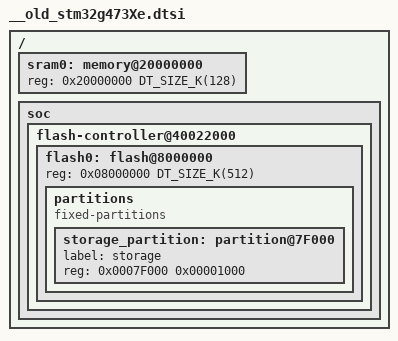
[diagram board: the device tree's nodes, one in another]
/*
 * Copyright (c) 2019 STMicroelectronics.
 *
 * SPDX-License-Identifier: Apache-2.0
 */

#include <mem.h>
#include "stm32g473.dtsi"

/ {
	sram0: memory@20000000 {
		reg = <0x20000000 DT_SIZE_K(128)>;
	};

	soc {
		flash-controller@40022000 {
			flash0: flash@8000000 {
				reg = <0x08000000 DT_SIZE_K(512)>;
			};
		};
	};
};

&flash0 {
	partitions {
		compatible = "fixed-partitions";
		#address-cells = <1>;
		#size-cells = <1>;

		/* 4KB partition used to store device settings */
		storage_partition: partition@7F000 {
			label = "storage";
			reg = <0x0007F000 0x00001000>;
		};
	};
};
